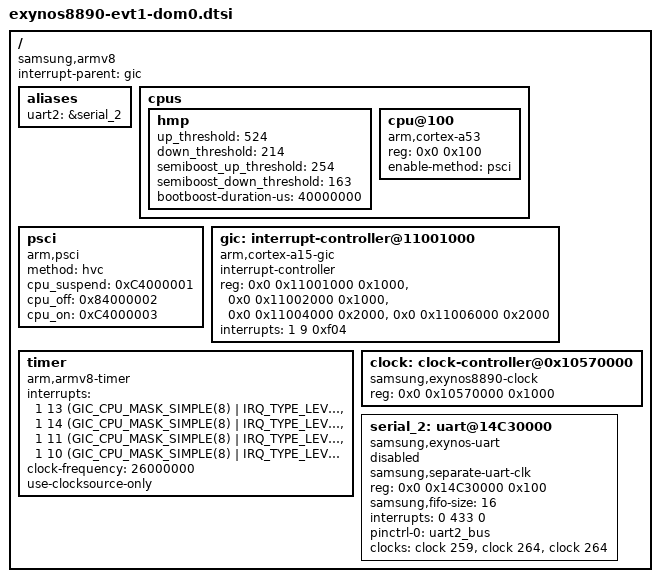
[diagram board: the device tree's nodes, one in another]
/*
 * SAMSUNG EXYNOS8890 SoC device tree source
 *
 * Copyright (c) 2014 Samsung Electronics Co., Ltd.
 *		http://www.samsung.com
 *
 * SAMSUNG EXYNOS8890 SoC device nodes are listed in this file.
 * EXYNOS8890 based board files can include this file and provide
 * values for board specfic bindings.
 *
 * This program is free software; you can redistribute it and/or modify
 * it under the terms of the GNU General Public License version 2 as
 * published by the Free Software Foundation.
 */

/memreserve/ 0xF0000000 0x8800000;     /* CP memory(128MB) + AP-CP shared memory(8MB) */
#include <dt-bindings/interrupt-controller/arm-gic.h>
#include <dt-bindings/clock/exynos8890.h>
#include "exynos8890-pinctrl.dtsi"
/ {
	compatible = "samsung,armv8", "samsung,exynos8890";
	interrupt-parent = <&gic>;
	#address-cells = <2>;
	#size-cells = <1>;

	aliases {
		uart2 = &serial_2;
	};

	cpus {
		#address-cells = <2>;
		#size-cells = <0>;

		hmp {
			up_threshold = <524>;
			down_threshold = <214>;
			semiboost_up_threshold = <254>;
			semiboost_down_threshold = <163>;
			bootboost-duration-us = <40000000>;
		};

		cpu@100 {
			device_type = "cpu";
			compatible = "arm,cortex-a53", "arm,armv8";
			reg = <0x0 0x100>;
			enable-method = "psci";
			/* cpu-idle-states = <&CPU_SLEEP_BOOT>; */
		};
	};

	psci {
                compatible = "arm,psci";
                method = "hvc";
                cpu_suspend = <0xC4000001>;
                cpu_off = <0x84000002>;
                cpu_on = <0xC4000003>;
        };

	gic:interrupt-controller@11001000 {
		compatible = "arm,cortex-a15-gic", "arm,cortex-a9-gic";
		#interrupt-cells = <3>;
		#address-cells = <0>;
		interrupt-controller;
		reg =	<0x0 0x11001000 0x1000>,
			<0x0 0x11002000 0x1000>,
			<0x0 0x11004000 0x2000>,
			<0x0 0x11006000 0x2000>;
		interrupts = <1 9 0xf04>;
	};

	timer {
	        compatible = "arm,armv8-timer";
	        interrupts = <1 13 (GIC_CPU_MASK_SIMPLE(8) | IRQ_TYPE_LEVEL_LOW)>,
	                     <1 14 (GIC_CPU_MASK_SIMPLE(8) | IRQ_TYPE_LEVEL_LOW)>,
	                     <1 11 (GIC_CPU_MASK_SIMPLE(8) | IRQ_TYPE_LEVEL_LOW)>,
	                     <1 10 (GIC_CPU_MASK_SIMPLE(8) | IRQ_TYPE_LEVEL_LOW)>;
	        clock-frequency = <26000000>;
		use-clocksource-only;
	};

	clock: clock-controller@0x10570000 {
		compatible = "samsung,exynos8890-clock";
		reg = <0x0 0x10570000 0x1000>;
		#clock-cells = <1>;
	};

	serial_2: uart@14C30000 {
		compatible = "samsung,exynos-uart";
		samsung,separate-uart-clk;
		reg = <0x0 0x14C30000 0x100>;
		samsung,fifo-size = <16>;
		interrupts = <0 433 0>;
		pinctrl-names = "default";
		pinctrl-0 = <&uart2_bus>;
		clocks = <&clock 259>, <&clock 264>, <&clock 264>;
		clock-names = "gate_pclk2", "gate_uart2", "sclk_uart2";
		status = "disabled";
	};
};
